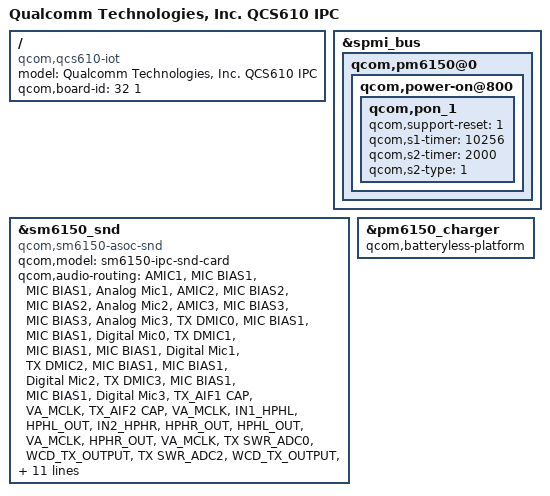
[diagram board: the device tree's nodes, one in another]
#include "qcs610-iot.dtsi"

/ {
	model = "Qualcomm Technologies, Inc. QCS610 IPC";
	compatible = "qcom,qcs610-iot", "qcom,qcs610", "qcom,iot";
	qcom,board-id = <32 1>;
};


&spmi_bus {
	qcom,pm6150@0 {
		qcom,power-on@800 {
			qcom,pon_1 {
				qcom,support-reset = <1>;
				qcom,s1-timer = <10256>;
				qcom,s2-timer = <2000>;
				qcom,s2-type = <1>;
			};
		};
	};
};

&sm6150_snd {
	status = "okay";
	compatible = "qcom,sm6150-asoc-snd";
	qcom,model = "sm6150-ipc-snd-card";
	qcom,audio-routing =
		"AMIC1", "MIC BIAS1",
		"MIC BIAS1", "Analog Mic1",
		"AMIC2", "MIC BIAS2",
		"MIC BIAS2", "Analog Mic2",
		"AMIC3", "MIC BIAS3",
		"MIC BIAS3", "Analog Mic3",
		"TX DMIC0", "MIC BIAS1",
		"MIC BIAS1", "Digital Mic0",
		"TX DMIC1", "MIC BIAS1",
		"MIC BIAS1", "Digital Mic1",
		"TX DMIC2", "MIC BIAS1",
		"MIC BIAS1", "Digital Mic2",
		"TX DMIC3", "MIC BIAS1",
		"MIC BIAS1", "Digital Mic3",
		"TX_AIF1 CAP", "VA_MCLK",
		"TX_AIF2 CAP", "VA_MCLK",
		"IN1_HPHL", "HPHL_OUT",
		"IN2_HPHR", "HPHR_OUT",
		"HPHL_OUT", "VA_MCLK",
		"HPHR_OUT", "VA_MCLK",
		"TX SWR_ADC0", "WCD_TX_OUTPUT",
		"TX SWR_ADC2", "WCD_TX_OUTPUT",
		"WSA SRC0_INP", "SRC0",
		"WSA_TX DEC0_INP", "TX DEC0 MUX",
		"WSA_TX DEC1_INP", "TX DEC1 MUX",
		"SpkrLeft IN", "WSA_SPK1 OUT",
		"WSA_SPK1 OUT", "VA_MCLK";
	qcom,wsa-max-devs = <1>;
	qcom,wsa-devs = <&wsa881x_0211>, <&wsa881x_0213>;
	qcom,wsa-aux-dev-prefix = "SpkrLeft", "SpkrLeft";
	qcom,linein-det-swh = <1>;
	qcom,lineout-det-swh = <1>;
	qcom,linein-det-gpio = <&tlmm 1 0>;
	qcom,lineout-det-gpio = <&tlmm 60 0>;
};

&pm6150_charger {
	qcom,batteryless-platform;
};
